# MB9AFA3xL register map
File version: 1.7
CPU: 
Registers are 8-bit, read-write, reset 0x0 unless marked. A register's access mark holds for its fields unless they carry their own. Offsets are from the block's base; [hi:lo] are bit positions; {n}, {i} and the like mark numbered series.

## LCDC — LCD Controller
Base 0x40032000
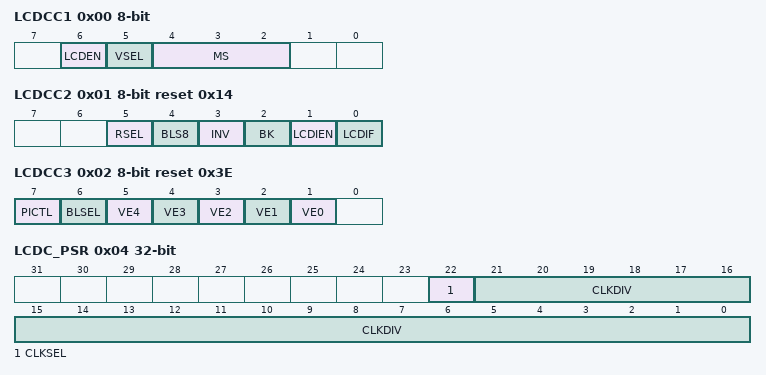
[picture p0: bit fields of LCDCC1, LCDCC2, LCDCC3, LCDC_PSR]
0x00 LCDCC1 — LCDC Control Register 1
  [6] LCDEN — Timer mode operation enable bit
  [5] VSEL — LCD drive power control bit
  [4:2] MS — LCD controller display mode selection bits
0x01 LCDCC2 reset 0x14 — LCDC Control Register 2
  [5] RSEL — Divider resistor value selection bit
  [4] BLS8 — 8 COM mode bias selection bit
  [3] INV — Reverse display control bit
  [2] BK — Blank display control bit
  [1] LCDIEN — Interrupt enable bit
  [0] LCDIF — Interrupt request detection bit
0x02 LCDCC3 reset 0x3E — LCDC Control Register 3
  [7] PICTL — I/O port input control bit
  [6] BLSEL — Blink interval selection bit
  [n+1] VE{n} (n=0..4) — VV{n} selection bit
0x04 LCDC_PSR 32-bit — LCDC Clock Prescaler Register
  [22] CLKSEL — Source clock selection bit
  [21:0] CLKDIV — LCDC clock division ratio setting bit
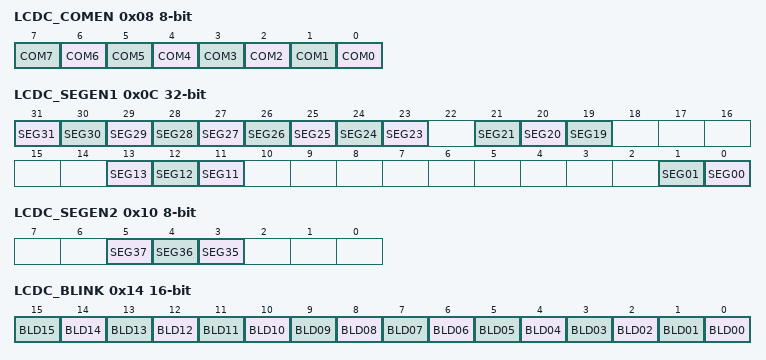
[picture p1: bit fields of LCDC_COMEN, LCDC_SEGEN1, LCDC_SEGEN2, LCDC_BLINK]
0x08 LCDC_COMEN — LCDC COM Output Enable Register
  [n] COM{n} (n=4..7) — Dual purpose COM/SEG port control bits
  [n] COM{n} (n=0..3) — Dual purpose COM port control bit
0x0C LCDC_SEGEN1 32-bit — LCDC SEG Output Enable Register 1
  [n] SEG{n} (n=23..31) — Segment {n}
  [21] SEG21 — Segment 21
  [20] SEG20 — Segment 20
  [19] SEG19 — Segment 19
  [13] SEG13 — Segment 13
  [12] SEG12 — Segment 12
  [11] SEG11 — Segment 11
  [1] SEG01 — Segment 1
  [0] SEG00 — Segment 0
0x10 LCDC_SEGEN2 — LCDC SEG Output Enable Register 2
  [5] SEG37 — Segment 37
  [4] SEG36 — Segment 36
  [3] SEG35 — Segment 35
0x14 LCDC_BLINK 16-bit — LCDC Blink Setting Register
  [n] BLD{n:02} (n=0..15) — Blink operation control bit {n}
{0x1C+i} LCDRAM{i:02} (i=0..39) — Display Data Memory Register {i:02}
  [7:0] LCDRAM — Display Data {i:02}

## HDMICEC0 — HDMI-CEC ch.0
Base 0x40034000
Same registers: HDMICEC1 0x40034100
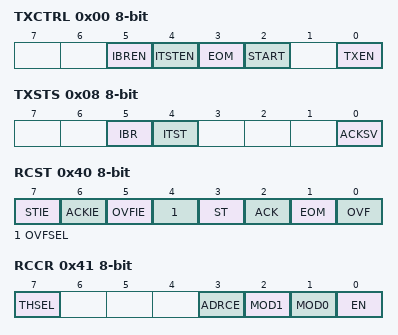
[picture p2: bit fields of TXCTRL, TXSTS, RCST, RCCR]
0x00 TXCTRL — Transmission Control Register
  [5] IBREN — Bus error detection interrupt enable bit
  [4] ITSTEN — transmission status interrupt enable bit
  [3] EOM — EOM setting bit
  [2] START — START setting bit
  [0] TXEN — Transmission operation enable bit
0x04 TXDATA — Transmission Data Register
  [7:0] TXDATA — Transmission Data
0x08 TXSTS — Transmission Status Register
  [5] IBR — Bus error detection interrupt request bit
  [4] ITST — Transmission status interrupt request bit
  [0] ACKSV — ACK cycle value bit
0x0C SFREE — Signal Free Time Setting Register
  [3:0] SFREE — Signal free time setting bits
0x40 RCST — Reception Interrupt Control Register
  [7] STIE — Start bit interrupt enable bit
  [6] ACKIE — ACK interrupt enable bit
  [5] OVFIE — Counter overflow interrupt enable bit
  [4] OVFSEL — Counter overflow detection condition setting bit
  [3] ST — Start bit detection bit
  [2] ACK — ACK: ACK detection bit
  [1] EOM — EOM detection bit
  [0] OVF — Counter overflow detection bit
0x41 RCCR — Reception Control Register
  [7] THSEL — Threshold selection bit
  [3] ADRCE — Address comparison enable bit
  [2] MOD1 — Operation mode setting bits
  [1] MOD0 — Operation mode setting bits
  [0] EN — Operation enable bit
0x44 RCDAHW — "H" Width Setting Register A
  [7:0] RCDAHW — "H" Width Setting A
0x45 RCSHW — Start Bit "H" Width Setting Register
  [7:0] RCSHW — Start Bit "H" Width Setting
0x49 RCDBHW — "H" Width Setting Register B
  [7:0] RCDBHW — "H" Width Setting B
0x4C RCADR2 — Device Address Setting Register 2
  [4:0] RCADR2 — Device Address 2
0x4D RCADR1 — Device Address Setting Register 1
  [4:0] RCADR1 — Device Address 1
0x50 RCDTHL ro — Data Save Register (High-Low)
0x51 RCDTHH ro — Data Save Register (High-High)
0x54 RCDTLL ro — Data Save Register (Low-Low)
0x55 RCDTLH ro — Data Save Register (Low-High)
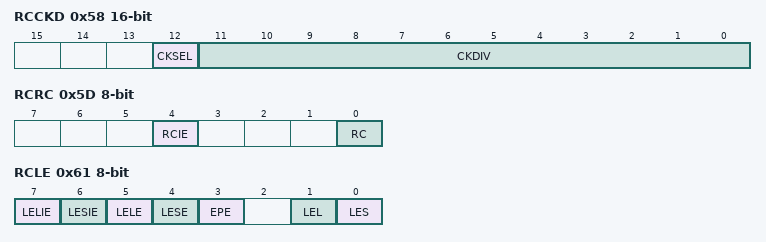
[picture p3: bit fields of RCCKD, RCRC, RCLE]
0x58 RCCKD 16-bit — Clock Division Setting Register
  [12] CKSEL — Operating clock selection bit
  [11:0] CKDIV — Operating clock division setting bits
0x5C RCRHW — Repeat Code "H" Width Setting Register
  [7:0] RCRHW — "Repeat code "H" width setting bits"
0x5D RCRC — Repeat Code Interrupt Control Register
  [4] RCIE — Repeat Code Interrupt enable bit
  [0] RC — Repeat code detection flag bit
0x61 RCLE — Data Bit Width Violation Control Register
  [7] LELIE — Maximum data bit width violation interrupt enable bit
  [6] LESIE — Minimum data bit width violation interrupt enable bit
  [5] LELE — Maximum data bit width violation detection enable bit
  [4] LESE — Minimum data bit width violation detection enable bit
  [3] EPE — Error pulse output enable bit
  [1] LEL — Maximum data bit width violation detection flag bit
  [0] LES — Minimum data bit width violation detection flag bit
0x64 RCLESW — Minimum Data Bit Width Setting Register
  [7:0] RCLESW — Minimum data bit width setting bits
0x65 RCLELW — Maximum Data Bit Width Setting Register
  [7:0] RCLELW — Maximum data bit width setting bits

## LVD — Low-voltage Detection
Base 0x40035000
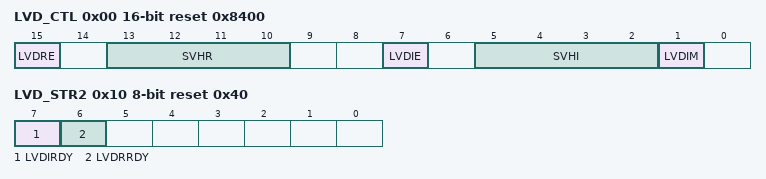
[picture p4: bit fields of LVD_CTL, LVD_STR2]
0x00 LVD_CTL 16-bit reset 0x8400 — Low-voltage Detection Voltage Control Register
  [15] LVDRE — Low-voltage detection reset operation enable bit
  [13:10] SVHR — Low-voltage detection reset voltage setting bits
  [7] LVDIE — Low-voltage detection interrupt enable bit
  [5:2] SVHI — Low-voltage detection interrupt voltage setting bits
  [1] LVDIM — Low-voltage detection interrupt low power mode select bit
0x04 LVD_STR ro — Low-voltage Detection Interrupt Register
  [7] LVDIR — Low-voltage detection interrupt bit
0x08 LVD_CLR reset 0x80 — Low-voltage Detection Interrupt Clear Register
  [7] LVDCL — Low-voltage detection interrupt clear bit
0x0C LVD_RLR 32-bit reset 0x1 — Low-voltage Detection Voltage Protection Register
  [31:0] LVDLCK — Low-voltage Detection Voltage Control Register protection bits
0x10 LVD_STR2 ro reset 0x40 — Low-voltage Detection Circuit Status Register
  [7] LVDIRDY — Low-voltage detection interrupt status flag
  [6] LVDRRDY — Low-voltage detection reset status flag

## DS — Low Power Consumption Mode
Base 0x40035100
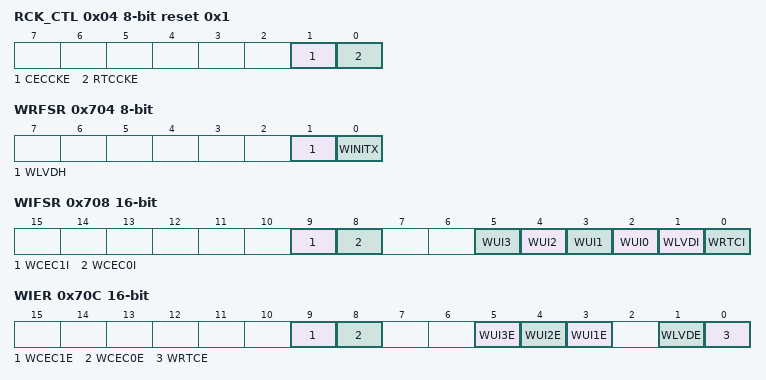
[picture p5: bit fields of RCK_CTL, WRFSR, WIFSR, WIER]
0x04 RCK_CTL reset 0x1 — Sub Clock Control Register
  [1] CECCKE — CEC clock control bit
  [0] RTCCKE — RTC clock control bit
0x700 PMD_CTL — RTC Mode Control Register
  [0] RTCE — RTC mode control bit
0x704 WRFSR — Deep Standby Return Cause Register 1
  [1] WLVDH — Low-voltage detection reset return bit
  [0] WINITX — INITX pin input reset return bit
0x708 WIFSR 16-bit ro — Deep Standby Return Cause Register 2
  [9] WCEC1I — CEC ch.1 interrupt return bit
  [8] WCEC0I — CEC ch.0 interrupt return bit
  [n+2] WUI{n} (n=0..3) — WKUP pin input return bit {n}
  [1] WLVDI — LVD interrupt return bit
  [0] WRTCI — RTC interrupt return bit
0x70C WIER 16-bit — Deep Standby Return Enable Register
  [9] WCEC1E — HDMI-CEC/ Remote Control Reception ch.1 interrupt return enable bit
  [8] WCEC0E — HDMI-CEC/ Remote Control Reception ch.0 interrupt return enable bit
  [5] WUI3E — WKUP pin input return enable bit 3
  [4] WUI2E — WKUP pin input return enable bit 2
  [3] WUI1E — WKUP pin input return enable bit 1
  [1] WLVDE — LVD interrupt return enable bit
  [0] WRTCE — RTC interrupt return enable bit
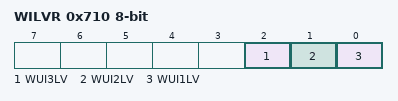
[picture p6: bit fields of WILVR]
0x710 WILVR — WKUP Pin Input Level Register
  [2] WUI3LV — WKUP pin input level select bit 3
  [1] WUI2LV — WKUP pin input level select bit 2
  [0] WUI1LV — WKUP pin input level select bit 1
{0x7FF+i} BUR{i:02} (i=1..16) — Backup Registers from {i}
